VERSION ""

NS_ :

BS_:

BU_:

BO_ 3221225472 VECTOR__INDEPENDENT_SIG_MSG: 0 Vector__XXX
 SG_ INUSE1 : 15|8@0+ (1,0) [0|0] "" Vector__XXX
 SG_ INUSE2 : 31|8@0+ (1,0) [0|0] "" Vector__XXX
 SG_ NewSignal_0007 : 7|8@0+ (1,0) [0|0] "" Vector__XXX
 SG_ NewSignal_0006 : 7|8@0+ (1,0) [0|0] "" Vector__XXX

BO_ 59 Msg3: 8 Vector__XXX

BO_ 971 Msg2: 7 Vector__XXX
 SG_ PackDCL : 0|1@0+ (1,0) [0|0] "" Vector__XXX
 SG_ PackCCL : 15|8@0+ (1,0) [0|0] "" Vector__XXX

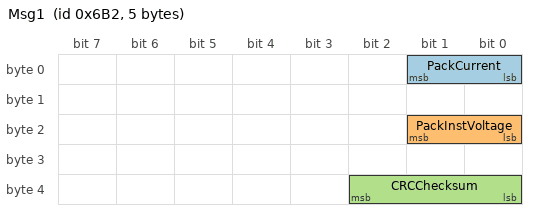
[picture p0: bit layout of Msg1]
BO_ 1714 Msg1: 5 Vector__XXX
 SG_ PackCurrent : 1|2@0+ (1,0) [0|0] "" Vector__XXX
 SG_ PackInstVoltage : 17|2@0+ (0.1,0) [0|0] "" Vector__XXX
 SG_ CRCChecksum : 34|3@0+ (1,64) [0|0] "" Vector__XXX

BA_DEF_  "BusType" STRING ;
BA_DEF_DEF_  "BusType" "CAN";
